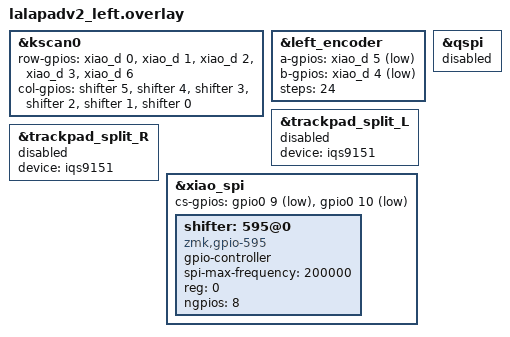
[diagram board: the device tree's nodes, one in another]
#include "lalapadv2.dtsi"

&kscan0 {
    row-gpios
        = <&xiao_d 0 (GPIO_ACTIVE_HIGH | GPIO_PULL_DOWN)> 
        , <&xiao_d 1 (GPIO_ACTIVE_HIGH | GPIO_PULL_DOWN)>
        , <&xiao_d 2 (GPIO_ACTIVE_HIGH | GPIO_PULL_DOWN)>
        , <&xiao_d 3 (GPIO_ACTIVE_HIGH | GPIO_PULL_DOWN)>
        , <&xiao_d 6 (GPIO_ACTIVE_HIGH | GPIO_PULL_DOWN)>
        ;
    col-gpios
        = <&shifter 5 GPIO_ACTIVE_HIGH>
        , <&shifter 4 GPIO_ACTIVE_HIGH>
        , <&shifter 3 GPIO_ACTIVE_HIGH>
        , <&shifter 2 GPIO_ACTIVE_HIGH>
        , <&shifter 1 GPIO_ACTIVE_HIGH>
        , <&shifter 0 GPIO_ACTIVE_HIGH>
        ;
};

&left_encoder {
    a-gpios = <&xiao_d 5 (GPIO_ACTIVE_LOW | GPIO_PULL_UP)>;
    b-gpios = <&xiao_d 4 (GPIO_ACTIVE_LOW | GPIO_PULL_UP)>;
    steps = <24>;
    status = "okay";
};

&trackpad_split_L {
    status = "disabled";
    device = <&iqs9151>;
};
&trackpad_split_R {
    status = "disabled";
    device = <&iqs9151>;
};

// SPI
&qspi {
	status = "disabled";
};
&xiao_spi {
    status = "okay";
    cs-gpios = <&gpio0 9 GPIO_ACTIVE_LOW>,<&gpio0 10 GPIO_ACTIVE_LOW>;

    shifter: 595@0 {
        compatible = "zmk,gpio-595";
        status = "okay";
        gpio-controller;
        spi-max-frequency = <200000>;
        reg = <0>;
        #gpio-cells = <2>;
        ngpios = <8>;
    };
};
